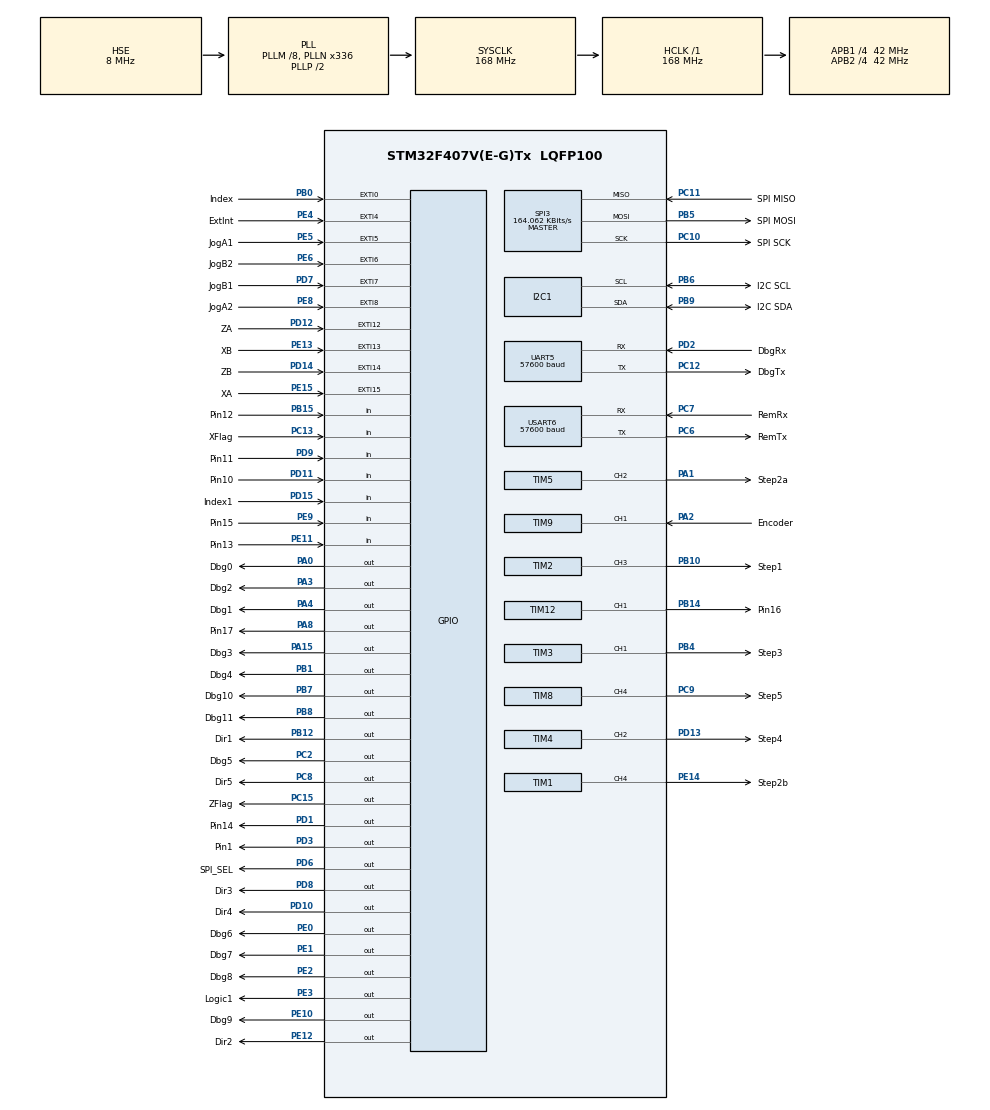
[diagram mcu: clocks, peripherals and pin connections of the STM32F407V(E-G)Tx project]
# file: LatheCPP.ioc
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Mcu.Family=STM32F4
Mcu.Name=STM32F407V(E-G)Tx
Mcu.Package=LQFP100
NVIC.EXTI0_IRQn=true\:5\:0\:true\:false\:false\:true\:false\:true
NVIC.EXTI15_10_IRQn=true\:3\:0\:true\:false\:false\:true\:false\:true
NVIC.EXTI4_IRQn=true\:2\:0\:true\:false\:false\:true\:false\:true
NVIC.EXTI9_5_IRQn=true\:3\:0\:true\:false\:false\:true\:false\:true
NVIC.PriorityGroup=NVIC_PRIORITYGROUP_4
NVIC.SPI3_IRQn=true\:6\:0\:true\:false\:false\:true\:false\:true
NVIC.TIM1_BRK_TIM9_IRQn=true\:5\:0\:true\:false\:false\:true\:false\:true
NVIC.TIM1_TRG_COM_TIM11_IRQn=true\:0\:0\:false\:false\:false\:true\:false\:true
NVIC.TIM1_UP_TIM10_IRQn=true\:4\:0\:true\:false\:false\:true\:false\:true
NVIC.TIM2_IRQn=true\:2\:0\:true\:false\:false\:true\:false\:true
NVIC.TIM3_IRQn=true\:2\:0\:true\:false\:false\:true\:false\:true
NVIC.TIM4_IRQn=true\:4\:0\:true\:false\:false\:true\:false\:true
NVIC.TIM5_IRQn=true\:2\:0\:true\:false\:false\:true\:false\:true
NVIC.TIM7_IRQn=true\:5\:0\:true\:false\:false\:true\:false\:true
NVIC.TIM8_BRK_TIM12_IRQn=true\:2\:0\:true\:false\:false\:true\:false\:true
NVIC.TIM8_TRG_COM_TIM14_IRQn=true\:0\:0\:false\:false\:false\:true\:false\:true
NVIC.TIM8_UP_TIM13_IRQn=true\:2\:0\:true\:false\:false\:true\:false\:true
NVIC.USART6_IRQn=true\:6\:0\:true\:false\:false\:true\:false\:true
PA0-WKUP.GPIO_Label=Dbg0
PA0-WKUP.Signal=GPIO_Output
PA1.GPIO_Label=Step2a
PA1.Signal=S_TIM5_CH2
PA13.Mode=Trace_Asynchronous_SW
PA13.Signal=SYS_JTMS-SWDIO
PA14.Mode=Trace_Asynchronous_SW
PA14.Signal=SYS_JTCK-SWCLK
PA15.GPIO_Label=Dbg3
PA15.Signal=GPIO_Output
PA2.GPIO_Label=Encoder
PA2.Signal=S_TIM9_CH1
PA3.GPIO_Label=Dbg2
PA3.Signal=GPIO_Output
PA4.GPIO_Label=Dbg1
PA4.Signal=GPIO_Output
PA8.GPIO_Label=Pin17
PA8.Signal=GPIO_Output
PB0.GPIO_Label=Index
PB0.Signal=GPXTI0
PB1.GPIO_Label=Dbg4
PB1.Signal=GPIO_Output
PB10.GPIO_Label=Step1
PB10.Signal=S_TIM2_CH3
PB12.GPIO_Label=Dir1
PB12.Signal=GPIO_Output
PB14.GPIO_Label=Pin16
PB14.Signal=S_TIM12_CH1
PB15.GPIO_Label=Pin12
PB15.Signal=GPIO_Input
PB3.Mode=Trace_Asynchronous_SW
PB3.Signal=SYS_JTDO-SWO
PB4.GPIO_Label=Step3
PB4.GPIO_Speed=GPIO_SPEED_FREQ_HIGH
PB4.Signal=S_TIM3_CH1
PB5.GPIO_Label=SPI MOSI
PB5.Mode=Full_Duplex_Master
PB5.Signal=SPI3_MOSI
PB6.GPIO_Label=I2C SCL
PB6.GPIO_Pu=GPIO_PULLUP
PB6.Mode=I2C
PB6.Signal=I2C1_SCL
PB7.GPIO_Label=Dbg10
PB7.Signal=GPIO_Output
PB8.GPIO_Label=Dbg11
PB8.Signal=GPIO_Output
PB9.GPIO_Label=I2C SDA
PB9.GPIO_Pu=GPIO_PULLUP
PB9.Mode=I2C
PB9.Signal=I2C1_SDA
PC10.GPIO_Label=SPI SCK
PC10.Mode=Full_Duplex_Master
PC10.Signal=SPI3_SCK
PC11.GPIO_Label=SPI MISO
PC11.Mode=Full_Duplex_Master
PC11.Signal=SPI3_MISO
PC12.GPIO_Label=DbgTx
PC12.Mode=Asynchronous
PC12.Signal=UART5_TX
PC13-ANTI_TAMP.GPIO_Label=XFlag
PC13-ANTI_TAMP.GPIO_PuPd=GPIO_PULLUP
PC13-ANTI_TAMP.Signal=GPIO_Input
PC15-OSC32_OUT.GPIO_Label=ZFlag
PC15-OSC32_OUT.Signal=GPIO_Output
PC2.GPIO_Label=Dbg5
PC2.Signal=GPIO_Output
PC6.GPIO_Label=RemTx
PC6.Mode=Asynchronous
PC6.Signal=USART6_TX
PC7.GPIO_Label=RemRx
PC7.Mode=Asynchronous
PC7.Signal=USART6_RX
PC8.GPIO_Label=Dir5
PC8.Signal=GPIO_Output
PC9.GPIO_Label=Step5
PC9.GPIO_Speed=GPIO_SPEED_FREQ_HIGH
PC9.Signal=S_TIM8_CH4
PD1.GPIO_Label=Pin14
PD1.Signal=GPIO_Output
PD10.GPIO_Label=Dir4
PD10.Signal=GPIO_Output
PD11.GPIO_Label=Pin10
PD11.Signal=GPIO_Input
PD12.GPIO_Label=ZA
PD12.GPIO_ModeDefaultEXTI=GPIO_MODE_IT_RISING_FALLING
PD12.Signal=GPXTI12
PD13.GPIO_Label=Step4
PD13.Signal=S_TIM4_CH2
PD14.GPIO_Label=ZB
PD14.GPIO_ModeDefaultEXTI=GPIO_MODE_IT_RISING_FALLING
PD14.Signal=GPXTI14
PD15.GPIO_Label=Index1
PD15.Signal=GPIO_Input
PD2.GPIO_Label=DbgRx
PD2.Mode=Asynchronous
PD2.Signal=UART5_RX
PD3.GPIO_Label=Pin1
PD3.Signal=GPIO_Output
PD6.GPIO_Label=SPI_SEL
PD6.Signal=GPIO_Output
PD7.GPIO_Label=JogB1
PD7.GPIO_ModeDefaultEXTI=GPIO_MODE_IT_RISING_FALLING
PD7.Signal=GPXTI7
PD8.GPIO_Label=Dir3
PD8.Signal=GPIO_Output
PD9.GPIO_Label=Pin11
PD9.Signal=GPIO_Input
PE0.GPIO_Label=Dbg6
PE0.Signal=GPIO_Output
PE1.GPIO_Label=Dbg7
PE1.Signal=GPIO_Output
PE10.GPIO_Label=Dbg9
PE10.Signal=GPIO_Output
PE11.GPIO_Label=Pin13
PE11.Signal=GPIO_Input
PE12.GPIO_Label=Dir2
PE12.Signal=GPIO_Output
PE13.GPIO_Label=XB
PE13.GPIO_ModeDefaultEXTI=GPIO_MODE_IT_RISING_FALLING
PE13.Signal=GPXTI13
PE14.GPIO_Label=Step2b
PE14.Signal=S_TIM1_CH4
PE15.GPIO_Label=XA
PE15.GPIO_ModeDefaultEXTI=GPIO_MODE_IT_RISING_FALLING
PE15.Signal=GPXTI15
PE2.GPIO_Label=Dbg8
PE2.GPIO_ModeDefaultOutputPP=GPIO_MODE_OUTPUT_PP
PE2.GPIO_PuPd=GPIO_NOPULL
PE2.GPIO_Speed=GPIO_SPEED_FREQ_LOW
PE2.Signal=GPIO_Output
PE3.GPIO_Label=Logic1
PE3.Signal=GPIO_Output
PE4.GPIO_Label=ExtInt
PE4.GPIO_ModeDefaultEXTI=GPIO_MODE_IT_RISING_FALLING
PE4.Signal=GPXTI4
PE5.GPIO_Label=JogA1
PE5.GPIO_ModeDefaultEXTI=GPIO_MODE_IT_RISING_FALLING
PE5.Signal=GPXTI5
PE6.GPIO_Label=JogB2
PE6.GPIO_ModeDefaultEXTI=GPIO_MODE_IT_RISING_FALLING
PE6.Signal=GPXTI6
PE8.GPIO_Label=JogA2
PE8.GPIO_ModeDefaultEXTI=GPIO_MODE_IT_RISING_FALLING
PE8.Signal=GPXTI8
PE9.GPIO_Label=Pin15
PE9.Signal=GPIO_Input
PH0-OSC_IN.Mode=HSE-External-Oscillator
PH0-OSC_IN.Signal=RCC_OSC_IN
PH1-OSC_OUT.Mode=HSE-External-Oscillator
PH1-OSC_OUT.Signal=RCC_OSC_OUT
ProjectManager.HeapSize=0x400
ProjectManager.StackSize=0x200
ProjectManager.TargetToolchain=STM32CubeIDE
RCC.48MHZClocksFreq_Value=48000000
RCC.AHBFreq_Value=168000000
RCC.APB1CLKDivider=RCC_HCLK_DIV4
RCC.APB1Freq_Value=42000000
RCC.APB1TimFreq_Value=84000000
RCC.APB2CLKDivider=RCC_HCLK_DIV4
RCC.APB2Freq_Value=42000000
RCC.APB2TimFreq_Value=84000000
RCC.CortexFreq_Value=168000000
RCC.HCLKFreq_Value=168000000
RCC.HSE_VALUE=8000000
RCC.HSI_VALUE=16000000
RCC.LSE_VALUE=32768
RCC.PLLM=8
RCC.PLLN=336
RCC.PLLQ=7
RCC.PLLSourceVirtual=RCC_PLLSOURCE_HSE
RCC.SYSCLKFreq_VALUE=168000000
RCC.SYSCLKSource=RCC_SYSCLKSOURCE_PLLCLK
RCC.VCOOutputFreq_Value=336000000
SH.S_TIM12_CH1.0=TIM12_CH1,PWM Generation1 CH1
SH.S_TIM1_CH4.0=TIM1_CH4,PWM Generation4 CH4
SH.S_TIM2_CH3.0=TIM2_CH3,PWM Generation3 CH3
SH.S_TIM3_CH1.0=TIM3_CH1,PWM Generation1 CH1
SH.S_TIM4_CH2.0=TIM4_CH2,PWM Generation2 CH2
SH.S_TIM5_CH2.0=TIM5_CH2,PWM Generation2 CH2
SH.S_TIM8_CH4.0=TIM8_CH4,PWM Generation4 CH4
SH.S_TIM9_CH1.0=TIM9_CH1,Input_Capture1_from_TI1
SPI3.BaudRatePrescaler=SPI_BAUDRATEPRESCALER_256
SPI3.CalculateBaudRate=164.062 KBits/s
SPI3.Direction=SPI_DIRECTION_2LINES
SPI3.Mode=SPI_MODE_MASTER
SPI3.VirtualType=VM_MASTER
TIM1.Channel-PWM\ Generation4\ CH4=TIM_CHANNEL_4
TIM1.CounterMode=TIM_COUNTERMODE_UP
TIM1.Period=65535
TIM1.Prescaler=0
TIM1.Pulse-PWM\ Generation4\ CH4=100
TIM10.Period=65535
TIM10.Prescaler=2560
TIM11.Period=10000
TIM12.Channel-PWM\ Generation1\ CH1=TIM_CHANNEL_1
TIM2.Channel-PWM\ Generation3\ CH3=TIM_CHANNEL_3
TIM2.CounterMode=TIM_COUNTERMODE_DOWN
TIM2.Period=100000
TIM2.Prescaler=0
TIM3.Channel-PWM\ Generation1\ CH1=TIM_CHANNEL_1
TIM3.CounterMode=TIM_COUNTERMODE_DOWN
TIM3.OCFastMode_PWM-PWM\ Generation1\ CH1=TIM_OCFAST_ENABLE
TIM3.Period=10000
TIM3.Pulse-PWM\ Generation1\ CH1=100
TIM3.TIM_MasterOutputTrigger=TIM_TRGO_UPDATE
TIM3.TIM_MasterSlaveMode=TIM_MASTERSLAVEMODE_ENABLE
TIM4.Channel-PWM\ Generation2\ CH2=TIM_CHANNEL_2
TIM4.CounterMode=TIM_COUNTERMODE_DOWN
TIM4.Period=9999
TIM4.TIM_MasterOutputTrigger=TIM_TRGO_UPDATE
TIM4.TIM_MasterSlaveMode=TIM_MASTERSLAVEMODE_DISABLE
TIM5.Channel-PWM\ Generation2\ CH2=TIM_CHANNEL_2
TIM5.CounterMode=TIM_COUNTERMODE_DOWN
TIM5.Period=100000
TIM5.Prescaler=0
TIM7.Period=10000
TIM8.Channel-PWM\ Generation4\ CH4=TIM_CHANNEL_4
TIM8.CounterMode=TIM_COUNTERMODE_DOWN
TIM8.Period=1000
TIM8.Prescaler=0
TIM8.Pulse-PWM\ Generation4\ CH4=100
TIM8.TIM_MasterOutputTrigger=TIM_TRGO_UPDATE
TIM8.TIM_MasterSlaveMode=TIM_MASTERSLAVEMODE_ENABLE
TIM9.Channel-Input_Capture1_from_TI1=TIM_CHANNEL_1
UART5.BaudRate=57600
UART5.VirtualMode=Asynchronous
USART6.BaudRate=57600
USART6.VirtualMode=VM_ASYNC
VP_IWDG_VS_IWDG.Mode=IWDG_Activate
VP_TIM10_VS_ClockSourceINT.Mode=Enable_Timer
VP_TIM11_VS_ClockSourceINT.Mode=Enable_Timer
VP_TIM12_VS_ClockSourceINT.Mode=Internal
VP_TIM1_VS_ClockSourceINT.Mode=Internal
VP_TIM2_VS_ClockSourceINT.Mode=Internal
VP_TIM3_VS_ClockSourceINT.Mode=Internal
VP_TIM4_VS_ClockSourceINT.Mode=Internal
VP_TIM4_VS_ClockSourceITR.Mode=TriggerSource_ITR2
VP_TIM4_VS_ControllerModeTrigger.Mode=Trigger Mode
VP_TIM5_VS_ClockSourceINT.Mode=Internal
VP_TIM6_VS_ClockSourceINT.Mode=Enable_Timer
VP_TIM7_VS_ClockSourceINT.Mode=Enable_Timer
VP_TIM8_VS_ClockSourceINT.Mode=Internal
board=Lathe

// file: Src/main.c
/* USER CODE BEGIN Header */
/**
  ******************************************************************************
  * @file           : main.c
  * @brief          : Main program body
  ******************************************************************************
  * @attention
  *
  * Copyright (c) 2022 STMicroelectronics.
  * All rights reserved.
  *
  * This software is licensed under terms that can be found in the LICENSE file
  * in the root directory of this software component.
  * If no LICENSE file comes with this software, it is provided AS-IS.
  *
  ******************************************************************************
  */
/* USER CODE END Header */
#include "main.h"
#include "i2c.h"
#include "iwdg.h"
#include "spi.h"
#include "tim.h"
#include "usart.h"
#include "gpio.h"

void SystemClock_Config(void);
/* USER CODE BEGIN PFP */

void mainLoop(void);

/* USER CODE END PFP */

int main(void)
{
  /* USER CODE BEGIN 1 */
  RCC->CFGR = 0;

  /* USER CODE END 1 */

  /* MCU Configuration--------------------------------------------------------*/

  /* Reset of all peripherals, Initializes the Flash interface and the Systick. */
  HAL_Init();

  /* Configure the system clock */
  SystemClock_Config();

  /* Initialize all configured peripherals */
  MX_GPIO_Init();
  MX_TIM1_Init();
  MX_TIM2_Init();
  MX_TIM3_Init();
  MX_TIM4_Init();
  MX_TIM5_Init();
  MX_TIM8_Init();
  MX_TIM12_Init();
  MX_UART5_Init();
  MX_USART6_UART_Init();
  MX_TIM7_Init();
  MX_TIM11_Init();
  MX_TIM10_Init();
  MX_I2C1_Init();
  MX_SPI3_Init();
  MX_TIM6_Init();
  MX_TIM9_Init();
  MX_IWDG_Init();
  /* USER CODE BEGIN 2 */

  mainLoop();

  /* USER CODE END 2 */

  /* Infinite loop */
  while (1)
  {

  }
}

void SystemClock_Config(void)
{
  RCC_OscInitTypeDef RCC_OscInitStruct = {0};
  RCC_ClkInitTypeDef RCC_ClkInitStruct = {0};

  /** Configure the main internal regulator output voltage
  */
  __HAL_RCC_PWR_CLK_ENABLE();
  __HAL_PWR_VOLTAGESCALING_CONFIG(PWR_REGULATOR_VOLTAGE_SCALE1);

  /** Initializes the RCC Oscillators according to the specified parameters
  * in the RCC_OscInitTypeDef structure.
  */
  RCC_OscInitStruct.OscillatorType = RCC_OSCILLATORTYPE_LSI|RCC_OSCILLATORTYPE_HSE;
  RCC_OscInitStruct.HSEState = RCC_HSE_ON;
  RCC_OscInitStruct.LSIState = RCC_LSI_ON;
  RCC_OscInitStruct.PLL.PLLState = RCC_PLL_ON;
  RCC_OscInitStruct.PLL.PLLSource = RCC_PLLSOURCE_HSE;
  RCC_OscInitStruct.PLL.PLLM = 8;
  RCC_OscInitStruct.PLL.PLLN = 336;
  RCC_OscInitStruct.PLL.PLLP = RCC_PLLP_DIV2;
  RCC_OscInitStruct.PLL.PLLQ = 7;
  if (HAL_RCC_OscConfig(&RCC_OscInitStruct) != HAL_OK)
  {
    Error_Handler();
  }

  /** Initializes the CPU, AHB and APB buses clocks
  */
  RCC_ClkInitStruct.ClockType = RCC_CLOCKTYPE_HCLK|RCC_CLOCKTYPE_SYSCLK
                              |RCC_CLOCKTYPE_PCLK1|RCC_CLOCKTYPE_PCLK2;
  RCC_ClkInitStruct.SYSCLKSource = RCC_SYSCLKSOURCE_PLLCLK;
  RCC_ClkInitStruct.AHBCLKDivider = RCC_SYSCLK_DIV1;
  RCC_ClkInitStruct.APB1CLKDivider = RCC_HCLK_DIV4;
  RCC_ClkInitStruct.APB2CLKDivider = RCC_HCLK_DIV4;

  if (HAL_RCC_ClockConfig(&RCC_ClkInitStruct, FLASH_LATENCY_5) != HAL_OK)
  {
    Error_Handler();
  }
}

void Error_Handler(void)
{
  __disable_irq();
  while (1)
  {
  }
}
